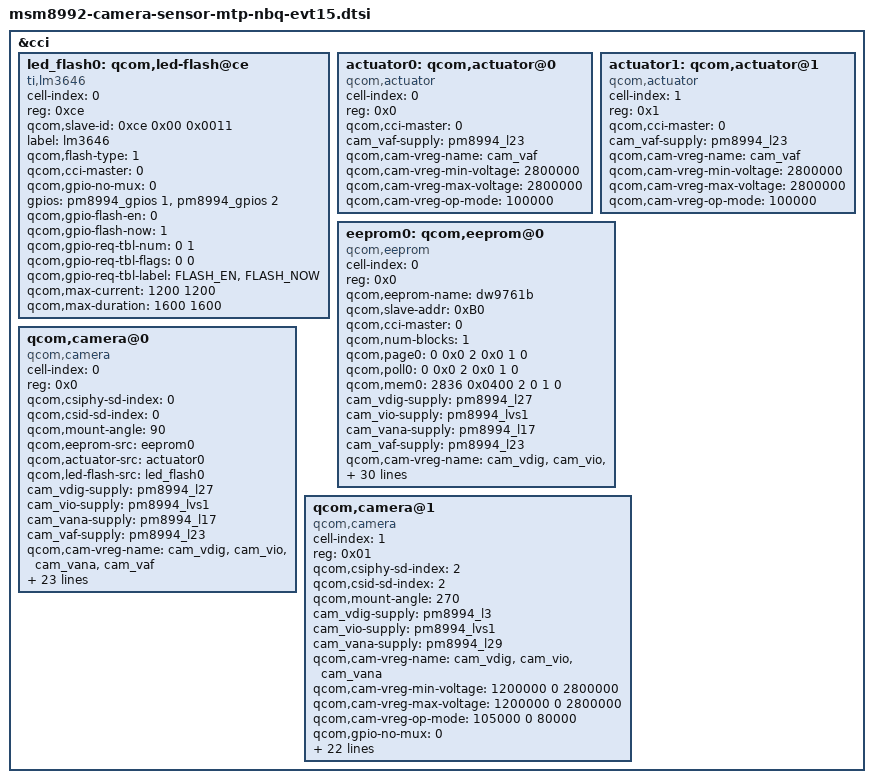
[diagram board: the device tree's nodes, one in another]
/*
 * Copyright (c) 2014-2015, The Linux Foundation. All rights reserved.
 *
 * This program is free software; you can redistribute it and/or modify
 * it under the terms of the GNU General Public License version 2 and
 * only version 2 as published by the Free Software Foundation.
 *
 * This program is distributed in the hope that it will be useful,
 * but WITHOUT ANY WARRANTY; without even the implied warranty of
 * MERCHANTABILITY or FITNESS FOR A PARTICULAR PURPOSE.  See the
 * GNU General Public License for more details.
 */
/*>>[ChunJengKang]:[Camera] porting flash led driver*/
/*
&soc {
	led_flash0: qcom,camera-led-flash {
		cell-index = <0>;
		compatible = "qcom,camera-led-flash";
		qcom,flash-type = <1>;
		qcom,flash-source = <&pmi8994_flash0 &pmi8994_flash1>;
		qcom,torch-source = <&pmi8994_torch0 &pmi8994_torch1>;
	};
};
*/

&cci {
	led_flash0: qcom,led-flash@ce {
		cell-index = <0>;
		reg = <0xce>;
		qcom,slave-id = <0xce 0x00 0x0011>;
		compatible = "ti,lm3646";
		label = "lm3646";
		qcom,flash-type = <1>;
		qcom,cci-master = <0>;
		qcom,gpio-no-mux = <0>;
		gpios = <&pm8994_gpios 1 0>,
		<&pm8994_gpios 2 0>;
		qcom,gpio-flash-en = <0>;
		qcom,gpio-flash-now = <1>;
		qcom,gpio-req-tbl-num = <0 1>;
		qcom,gpio-req-tbl-flags = <0 0>;
		qcom,gpio-req-tbl-label = "FLASH_EN",
			"FLASH_NOW";
		qcom,max-current = <1200 1200>;
		qcom,max-duration = <1600 1600>;
};
/*<<[ChunJengKang]:[Camera] porting flash led driver*/

	actuator0: qcom,actuator@0 {
		cell-index = <0>;
		reg = <0x0>;
		compatible = "qcom,actuator";
		qcom,cci-master = <0>;
		cam_vaf-supply = <&pm8994_l23>;
		qcom,cam-vreg-name = "cam_vaf";
		qcom,cam-vreg-min-voltage = <2800000>;
		qcom,cam-vreg-max-voltage = <2800000>;
		qcom,cam-vreg-op-mode = <100000>;
	};

	actuator1: qcom,actuator@1 {
		cell-index = <1>;
		reg = <0x1>;
		compatible = "qcom,actuator";
		qcom,cci-master = <0>;
		cam_vaf-supply = <&pm8994_l23>;
		qcom,cam-vreg-name = "cam_vaf";
		qcom,cam-vreg-min-voltage = <2800000>;
		qcom,cam-vreg-max-voltage = <2800000>;
		qcom,cam-vreg-op-mode = <100000>;
	};

	eeprom0: qcom,eeprom@0 {
		cell-index = <0>;
		reg = <0x0>;
		qcom,eeprom-name = "dw9761b";
		compatible = "qcom,eeprom";
		qcom,slave-addr = <0xB0>;
		qcom,cci-master = <0>;
/*>>ClarkIHLin[NBQ-76]:[Camera] Enable S5K3m2xm EEPROM*/
		qcom,num-blocks = <1>;

		qcom,page0 = <0 0x0 2 0x0 1 0>;
		qcom,poll0 = <0 0x0 2 0x0 1 0>;
		qcom,mem0 = <2836 0x0400 2 0 1 0>;
/*<<ClarkIHLin[NBQ-76]:[Camera] Enable S5K3m2xm EEPROM*/

//		cam_vdig-supply = <&pm8994_l25>;   // for EVB
		cam_vdig-supply = <&pm8994_l27>;     // for EVT1
		cam_vio-supply = <&pm8994_lvs1>;
		cam_vana-supply = <&pm8994_l17>;
		cam_vaf-supply = <&pm8994_l23>;
		qcom,cam-vreg-name = "cam_vdig", "cam_vio", "cam_vana", "cam_vaf";
		qcom,cam-vreg-type = <0 0 0 0>;
		qcom,cam-vreg-min-voltage = <1050000 0 2800000 2800000>;
		qcom,cam-vreg-max-voltage = <1050000 0 2800000 2800000>;
		qcom,cam-vreg-op-mode = <105000 0 80000 100000>;
		qcom,gpio-no-mux = <0>;
		pinctrl-names = "cam_default", "cam_suspend";
		pinctrl-0 = <&cam_sensor_mclk0_active &cam_sensor_rear_active>;
		pinctrl-1 = <&cam_sensor_mclk0_suspend &cam_sensor_rear_suspend>;
		gpios = <&msm_gpio 13 0>,
			<&msm_gpio 92 0>,
			<&msm_gpio 69 0>;
		qcom,gpio-reset = <1>;
		qcom,gpio-vaf = <2>;
//		qcom,gpio-standby = <2>;
		qcom,gpio-req-tbl-num = <0 1 2>;
		qcom,gpio-req-tbl-flags = <1 0 0>;
		qcom,gpio-req-tbl-label = "CAMIF_MCLK0",
					  "CAM_RESET0",
					  "CAM_VAF_EN0";
		qcom,cam-power-seq-type = "sensor_vreg", "sensor_vreg",
			"sensor_vreg", "sensor_vreg", "sensor_gpio", "sensor_gpio",
			"sensor_clk";
		qcom,cam-power-seq-val = "cam_vdig", "cam_vana", "cam_vio",
			"cam_vaf", "sensor_gpio_reset", "sensor_gpio_vaf",
			"sensor_cam_mclk";
		qcom,cam-power-seq-cfg-val = <1 1 1 1 1 1 24000000>;
		qcom,cam-power-seq-delay = <1 1 1 1 30 1 5>;
		status = "ok";
		clocks = <&clock_mmss clk_mclk0_clk_src>,
				<&clock_mmss clk_camss_mclk0_clk>;
		clock-names = "cam_src_clk", "cam_clk";
	};

	qcom,camera@0 {
		cell-index = <0>;
		compatible = "qcom,camera";
		reg = <0x0>;
		qcom,csiphy-sd-index = <0>;
		qcom,csid-sd-index = <0>;
		qcom,mount-angle = <90>;
/*>>ClarkIHLin[NBQ-76]:[Camera] Enable S5K3m2xm EEPROM*/
		qcom,eeprom-src = <&eeprom0>;
/*<<ClarkIHLin[NBQ-76]:[Camera] Enable S5K3m2xm EEPROM*/
		qcom,actuator-src = <&actuator0>;
//		qcom,ois-src = <&ois0>;
		qcom,led-flash-src = <&led_flash0>;
		cam_vdig-supply = <&pm8994_l27>;
		cam_vio-supply = <&pm8994_lvs1>;
		cam_vana-supply = <&pm8994_l17>;
		cam_vaf-supply = <&pm8994_l23>;
		qcom,cam-vreg-name = "cam_vdig", "cam_vio", "cam_vana", "cam_vaf";
		qcom,cam-vreg-type = <0 0 0 0>;
		qcom,cam-vreg-min-voltage = <1050000 0 2800000 2800000>;
		qcom,cam-vreg-max-voltage = <1050000 0 2800000 2800000>;
		qcom,cam-vreg-op-mode = <105000 0 80000 100000>;
		qcom,gpio-no-mux = <0>;
		pinctrl-names = "cam_default", "cam_suspend";
		pinctrl-0 = <&cam_sensor_mclk0_active &cam_sensor_rear_active>;
		pinctrl-1 = <&cam_sensor_mclk0_suspend &cam_sensor_rear_suspend>;
		gpios = <&msm_gpio 13 0>,
			<&msm_gpio 92 0>,
			<&msm_gpio 69 0>;
		qcom,gpio-reset = <1>;
		qcom,gpio-vaf = <2>;
		qcom,gpio-req-tbl-num = <0 1 2>;
		qcom,gpio-req-tbl-flags = <1 0 0>;
		qcom,gpio-req-tbl-label = "CAMIF_MCLK0",
					  "CAM_RESET0",
					  "CAM_VAF_EN0";
		qcom,sensor-position = <0>;
		qcom,sensor-mode = <0>;
		qcom,cci-master = <0>;
		status = "ok";
		clocks = <&clock_mmss clk_mclk0_clk_src>,
				<&clock_mmss clk_camss_mclk0_clk>;
		clock-names = "cam_src_clk", "cam_clk";
	};

	qcom,camera@1 {
		cell-index = <1>;
		compatible = "qcom,camera";
		reg = <0x01>;
		qcom,csiphy-sd-index = <2>;
		qcom,csid-sd-index = <2>;
		qcom,mount-angle = <270>;
		cam_vdig-supply = <&pm8994_l3>;
		cam_vio-supply = <&pm8994_lvs1>;   ///EVT1.5: i2c power
		cam_vana-supply = <&pm8994_l29>;
		qcom,cam-vreg-name = "cam_vdig", "cam_vio", "cam_vana";
		qcom,cam-vreg-min-voltage = <1200000 0 2800000>;
		qcom,cam-vreg-max-voltage = <1200000 0 2800000>;
		qcom,cam-vreg-op-mode = <105000 0 80000>;
		qcom,gpio-no-mux = <0>;
		pinctrl-names = "cam_default", "cam_suspend";
		pinctrl-0 = <&cam_sensor_mclk2_active &cam_sensor_front_active>;
		pinctrl-1 = <&cam_sensor_mclk2_suspend &cam_sensor_front_suspend>;
		gpios = <&msm_gpio 15 0>,
			<&msm_gpio 102 0>;
		qcom,gpio-reset = <1>;
		qcom,gpio-req-tbl-num = <0 1>;
		qcom,gpio-req-tbl-flags = <1 0>;
		qcom,gpio-req-tbl-label = "CAMIF_MCLK2",
					  "CAM_RESET2";
		qcom,cam-power-seq-type = "sensor_vreg", "sensor_vreg", "sensor_vreg",
			"sensor_gpio", "sensor_clk";
		qcom,cam-power-seq-val = "cam_vdig", "cam_vana", "cam_vio",
			"sensor_gpio_reset", "sensor_cam_mclk";
		qcom,cam-power-seq-cfg-val = <1 1 1 1 24000000>;
		qcom,cam-power-seq-delay = <1 1 1 30 5>;
		qcom,sensor-position = <1>;
		qcom,sensor-mode = <1>;
//		qcom,cci-master = <0>;    // for EVB
		qcom,cci-master = <1>;      // for EVT1
		status = "ok";
		clocks = <&clock_mmss clk_mclk2_clk_src>,
			<&clock_mmss clk_camss_mclk2_clk>;
		clock-names = "cam_src_clk", "cam_clk";
	};
};
